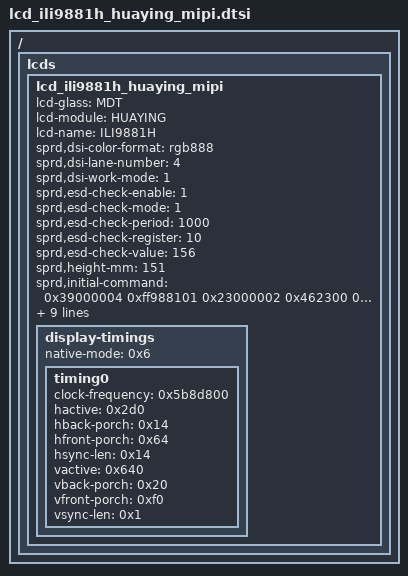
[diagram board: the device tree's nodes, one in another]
/ {
	fragment {
		target-path = "/";
		__overlay__ {
			lcds {
				lcd_ili9881h_huaying_mipi: lcd_ili9881h_huaying_mipi {
					lcd-glass = "MDT";
					lcd-module = "HUAYING";
					lcd-name = "ILI9881H";
					
					sprd,dsi-color-format = "rgb888";
					sprd,dsi-lane-number = <4>;
					sprd,dsi-work-mode = <1>;
					
					sprd,esd-check-enable = <1>;
					sprd,esd-check-mode = <1>;
					sprd,esd-check-period = <1000>;
					sprd,esd-check-register = <10>;
					sprd,esd-check-value = <156>;
					sprd,height-mm = <151>;
					sprd,initial-command = <0x39000004 0xff988101 0x23000002 0x462300 0x20116 0x23000002 0x2002300 0x20300 0x23000002 0x8802300 0x2090a 0x23000002 0xa712300 0x20b00 0x23000002 0xc002300 0x20d00 0x23000002 0xe012300 0x20f01 0x23000002 0x10012300 0x21101 0x23000002 0x12012300 0x22401 0x23000002 0x250b2300 0x22600 0x23000002 0x27002300 0x23121 0x23000002 0x32072300 0x23301 0x23000002 0x34002300 0x23502 0x23000002 0x36072300 0x23707 0x23000002 0x38072300 0x23907 0x23000002 0x3a172300 0x23b15 0x23000002 0x3c072300 0x23d07 0x23000002 0x3e132300 0x23f11 0x23000002 0x40092300 0x24107 0x23000002 0x42072300 0x24307 0x23000002 0x44072300 0x24507 0x23000002 0x46072300 0x24720 0x23000002 0x48072300 0x24901 0x23000002 0x4a002300 0x24b02 0x23000002 0x4c072300 0x24d07 0x23000002 0x4e072300 0x24f07 0x23000002 0x50162300 0x25114 0x23000002 0x52072300 0x25307 0x23000002 0x54122300 0x25510 0x23000002 0x56082300 0x25707 0x23000002 0x58072300 0x25907 0x23000002 0x5a072300 0x25b07 0x23000002 0x5c072300 0x26108 0x23000002 0x62072300 0x26301 0x23000002 0x64002300 0x26502 0x23000002 0x66072300 0x26707 0x23000002 0x68072300 0x26907 0x23000002 0x6a102300 0x26b12 0x23000002 0x6c072300 0x26d07 0x23000002 0x6e142300 0x26f16 0x23000002 0x70202300 0x27107 0x23000002 0x72072300 0x27307 0x23000002 0x74072300 0x27507 0x23000002 0x76072300 0x27709 0x23000002 0x78072300 0x27901 0x23000002 0x7a002300 0x27b02 0x23000002 0x7c072300 0x27d07 0x23000002 0x7e072300 0x27f07 0x23000002 0x80112300 0x28113 0x23000002 0x82072300 0x28307 0x23000002 0x84152300 0x28517 0x23000002 0x86212300 0x28707 0x23000002 0x88072300 0x28907 0x23000002 0x8a072300 0x28b07 0x23000002 0x8c072300 0x2b012 0x23000002 0xb1332300 0x2b222 0x23000002 0xb9402300 0x2d001 0x23000002 0xd1002300 0x2dc35 0x23000002 0xdd422300 0x2e200 0x23000002 0xe6222300 0x2e754 0x39000004 0xff988102 0x23000002 0x404a2300 0x24b5a 0x23000002 0x4d4e2300 0x24e00 0x23000002 0x1a483900 0x4ff98 0x81052300 0x20300 0x23000002 0x4cc2300 0x20dca 0x23000002 0x58622300 0x2637e 0x23000002 0x647e2300 0x268a1 0x23000002 0x69a72300 0x26aa1 0x23000002 0x6b933900 0x4ff98 0x81062300 0x22e01 0x23000002 0xc01f2300 0x2c103 0x39000004 0xff988106 0x23000002 0x11032300 0x21344 0x23000002 0x14412300 0x215f1 0x23000002 0x16402300 0x2c204 0x23000002 0x27202300 0x22820 0x23000002 0x480f2300 0x24d80 0x23000002 0x4e402300 0x27f78 0x23000002 0xd6872300 0x2dd18 0x39000004 0xff988108 0x3900001c 0xe0002470 0xa2df5511 0x366387a5 0xbde91036 0xaa5f92b3 0xdeff0331 0x6b9803ec 0x3900001c 0xe1002470 0xa2df5511 0x366387a5 0xbde91036 0xaa5f92b3 0xdeff0331 0x6b9803ec 0x39000004 0xff98810e 0x23000002 0xa02300 0x20126 0x23000002 0x11902300 0x21310 0x39000004 0xff988103 0x23000002 0xbc062300 0x283e0 0x23000002 0x84073900 0x4ff98 0x81003900 0x35100 0x390000 0x3680400 0x23000002 0x55002378 0x21100 0x23640002 0x29002300 0x23500>;
					sprd,phy-bit-clock = <0xa8b38>;
					sprd,phy-escape-clock = <0x4e20>;
					sprd,reset-on-sequence = <0x1 0xa 0x0 0xa 0x1 0x14>;
					sprd,sleep-in-command = <0x231e0002 0x28002396 0x21000>;
					sprd,sleep-out-command = [23 96 00 02 11 00 23 1e 00 02 29 00 23 00 00 02 35 00];
					sprd,width-mm = <0x44>;

					display-timings {
						native-mode = <0x6>;

						timing0 {
							clock-frequency = <0x5b8d800>;
							hactive = <0x2d0>;
							hback-porch = <0x14>;
							hfront-porch = <0x64>;
							hsync-len = <0x14>;
							phandle = <0x6>;
							vactive = <0x640>;
							vback-porch = <0x20>;
							vfront-porch = <0xf0>;
							vsync-len = <0x1>;
						};
					};
				};
			};
		};
	};
};

